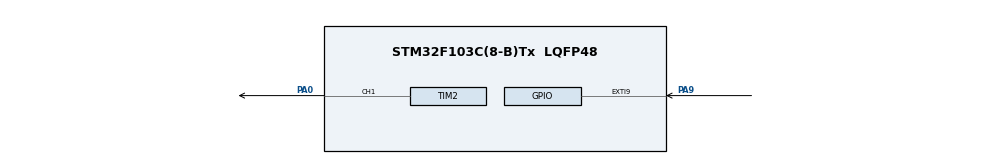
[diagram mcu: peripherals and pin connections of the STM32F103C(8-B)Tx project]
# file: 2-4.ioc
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Mcu.Family=STM32F1
Mcu.Name=STM32F103C(8-B)Tx
Mcu.Package=LQFP48
NVIC.EXTI9_5_IRQn=true\:15\:0\:true\:false\:true\:true\:true\:true
NVIC.PriorityGroup=NVIC_PRIORITYGROUP_4
NVIC.TIM3_IRQn=true\:15\:0\:true\:false\:true\:true\:true\:true
PA0-WKUP.Signal=S_TIM2_CH1_ETR
PA13.Mode=Serial_Wire
PA13.Signal=SYS_JTMS-SWDIO
PA14.Mode=Serial_Wire
PA14.Signal=SYS_JTCK-SWCLK
PA9.GPIO_ModeDefaultEXTI=GPIO_MODE_IT_FALLING
PA9.GPIO_PuPd=GPIO_PULLUP
PA9.Signal=GPXTI9
PD0-OSC_IN.Mode=HSE-External-Oscillator
PD0-OSC_IN.Signal=RCC_OSC_IN
PD1-OSC_OUT.Mode=HSE-External-Oscillator
PD1-OSC_OUT.Signal=RCC_OSC_OUT
ProjectManager.HeapSize=0x200
ProjectManager.StackSize=0x400
ProjectManager.TargetToolchain=CMake
RCC.APB1Freq_Value=8000000
RCC.APB2Freq_Value=8000000
SH.S_TIM2_CH1_ETR.0=TIM2_CH1,PWM Generation1 CH1
TIM2.Channel-PWM\ Generation1\ CH1=TIM_CHANNEL_1
TIM2.Period=999
TIM2.Prescaler=7
TIM3.Period=999
TIM3.Prescaler=7
VP_TIM2_VS_ClockSourceINT.Mode=Internal
VP_TIM3_VS_ClockSourceINT.Mode=Internal
board=custom

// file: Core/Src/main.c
/* USER CODE BEGIN Header */
/**
  ******************************************************************************
  * @file           : main.c
  * @brief          : Main program body
  ******************************************************************************
  * @attention
  *
  * Copyright (c) 2026 STMicroelectronics.
  * All rights reserved.
  *
  * This software is licensed under terms that can be found in the LICENSE file
  * in the root directory of this software component.
  * If no LICENSE file comes with this software, it is provided AS-IS.
  *
  ******************************************************************************
  */
/* USER CODE END Header */
#include "main.h"
#include "tim.h"
#include "gpio.h"

/* USER CODE BEGIN PV */
 int mode1=1,mode2=-1; //模式选择
 int ccr=0;  //占空比
 uint32_t l_time=0,n_time=0; //get时间
 int jin=0; //按键按下标志
 int breath=1; //呼吸灯标志
/* USER CODE END PV */

void SystemClock_Config(void);

int main(void)
{

  /* MCU Configuration--------------------------------------------------------*/

  /* Reset of all peripherals, Initializes the Flash interface and the Systick. */
  HAL_Init();

  /* Configure the system clock */
  SystemClock_Config();

  /* Initialize all configured peripherals */
  MX_GPIO_Init();
  MX_TIM2_Init();
  MX_TIM3_Init();
  /* USER CODE BEGIN 2 */
HAL_TIM_PWM_Start(&htim2, TIM_CHANNEL_1); //启动pwm口
HAL_TIM_Base_Start_IT(&htim3); //启动定时器3
  /* USER CODE END 2 */

  /* Infinite loop */
  while (1)
  {

    /* USER CODE BEGIN 3 */
    if(jin==1)//判断按钮
    {
      if(HAL_GPIO_ReadPin(GPIOA, GPIO_PIN_9)==GPIO_PIN_SET) //判断按键松开的时间
      {
        jin=0; //按键松开
        n_time=HAL_GetTick(); //获取当前时间
        if(n_time-l_time>1000) //判断是否超过1s
        {
          mode2 *=-1; //长按切换呼吸灯
          if(mode2==-1) //判断是否为呼吸灯模式
          {
            ccr=250*mode1; //更新占空比
          }
          else
          {
            breath=1; //调整呼吸灯标志
            ccr=0; //更新占空比
          }
        }

        else if(mode2==-1)//判断是否为呼吸灯模式,切换模式1
        {
          if(mode1==4) //切换模式1至1
        {
         mode1=1;
        }
        else
        {
        mode1 +=1; //切换模式
         }
        ccr=250*mode1; //更新占空比
        }
      }
    }
    __HAL_TIM_SET_COMPARE(&htim2, TIM_CHANNEL_1, ccr); //更新占空比
  }
  /* USER CODE END 3 */
}

void SystemClock_Config(void)
{
  RCC_OscInitTypeDef RCC_OscInitStruct = {0};
  RCC_ClkInitTypeDef RCC_ClkInitStruct = {0};

  /** Initializes the RCC Oscillators according to the specified parameters
  * in the RCC_OscInitTypeDef structure.
  */
  RCC_OscInitStruct.OscillatorType = RCC_OSCILLATORTYPE_HSI;
  RCC_OscInitStruct.HSIState = RCC_HSI_ON;
  RCC_OscInitStruct.HSICalibrationValue = RCC_HSICALIBRATION_DEFAULT;
  RCC_OscInitStruct.PLL.PLLState = RCC_PLL_NONE;
  if (HAL_RCC_OscConfig(&RCC_OscInitStruct) != HAL_OK)
  {
    Error_Handler();
  }

  /** Initializes the CPU, AHB and APB buses clocks
  */
  RCC_ClkInitStruct.ClockType = RCC_CLOCKTYPE_HCLK|RCC_CLOCKTYPE_SYSCLK
                              |RCC_CLOCKTYPE_PCLK1|RCC_CLOCKTYPE_PCLK2;
  RCC_ClkInitStruct.SYSCLKSource = RCC_SYSCLKSOURCE_HSI;
  RCC_ClkInitStruct.AHBCLKDivider = RCC_SYSCLK_DIV1;
  RCC_ClkInitStruct.APB1CLKDivider = RCC_HCLK_DIV1;
  RCC_ClkInitStruct.APB2CLKDivider = RCC_HCLK_DIV1;

  if (HAL_RCC_ClockConfig(&RCC_ClkInitStruct, FLASH_LATENCY_0) != HAL_OK)
  {
    Error_Handler();
  }
}

/* USER CODE BEGIN 4 */
void HAL_GPIO_EXTI_Callback(uint16_t GPIO_Pin)
{
  if(GPIO_Pin==GPIO_PIN_9) //判断是否为PA9中断
  {
    n_time=HAL_GetTick(); //获取当前时间
    if(n_time-l_time>20) //判断是否超过20ms，消抖
    {
      jin=1; //按键按下
    }
  }
  l_time=n_time; //更新上次时间
}
void HAL_TIM_PeriodElapsedCallback(TIM_HandleTypeDef *htim)
{
  if(htim->Instance==TIM3) //判断是否为定时器3中断
  {
    if(mode2==1)//判断模式
    {
      if(ccr>=1000)//判断占空比
      {
        breath=-1; //占空比清零
      }
      else if(ccr<=0)
      {
        breath=1; //占空比满
      }
      if(breath==1) //判断呼吸灯标志
      {
        ccr+=1; //占空比增加
      }
      else if(breath==-1)
      {
        ccr-=1; //占空比减少
      }
    }
  }
}
/* USER CODE END 4 */

void Error_Handler(void)
{
  __disable_irq();
  while (1)
  {
  }
}
